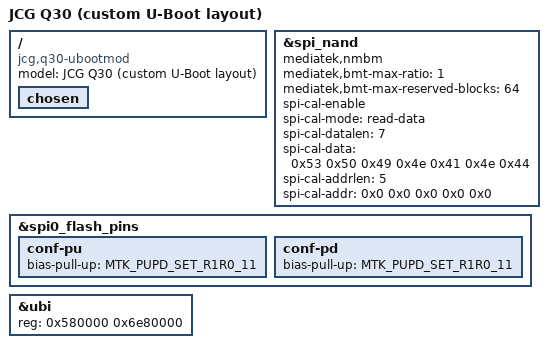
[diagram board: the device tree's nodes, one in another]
// SPDX-License-Identifier: GPL-2.0-or-later OR MIT
/*
 * JCG Q30 / Q30 PRO (custom U-Boot layout)
 *
 * Ported from the ImmortalWrt openwrt-23.05 mt7981b-jcg-q30-ubootmod.dts.
 * The vendor "unbrickable" U-Boot (kept in the "fip" partition) boots a
 * FIT image from the "kernel" UBI volume and keeps its environment in
 * the "u-boot-env" MTD partition, so this variant keeps the classic
 * kernel/rootfs/rootfs_data UBI layout instead of the single "fit"
 * volume used by the OpenWrt U-Boot layout.
 *
 * Copyright (C) 2023 Tianling Shen <cnsztl@immortalwrt.org>
 */

/dts-v1/;
#include <dt-bindings/pinctrl/mt65xx.h>

#include "mt7981b-jcg-q30-pro.dts"

/ {
	model = "JCG Q30 (custom U-Boot layout)";

	compatible = "jcg,q30-ubootmod", "mediatek,mt7981";

	/* The vendor U-Boot environment carries the bootargs
	 * (root=/dev/ubiblock0_x rootfstype=squashfs); do not force
	 * the OpenWrt U-Boot layout's "root=/dev/fit0" here.
	 */
	chosen {
		/delete-property/ bootargs-append;
		/delete-property/ rootdisk;
	};
};

&spi_nand {
	/* 6.6's MTK_BMT module (CONFIG_MTD_NAND_MTK_BMT=y in the
	 * mediatek/filogic kernel config) provides NMBM remapping;
	 * mtk_bmt_nmbm.c still parses the bmt-max-* tuning
	 * properties, kept as in the 23.05 ubootmod DTS.
	 */
	mediatek,nmbm;
	mediatek,bmt-max-ratio = <1>;
	mediatek,bmt-max-reserved-blocks = <64>;

	spi-cal-enable;
	spi-cal-mode = "read-data";
	spi-cal-datalen = <7>;
	spi-cal-data = /bits/ 8 <0x53 0x50 0x49 0x4e 0x41 0x4e 0x44>;
	spi-cal-addrlen = <5>;
	spi-cal-addr = /bits/ 32 <0x0 0x0 0x0 0x0 0x0>;
};

&spi0_flash_pins {
	conf-pu {
		/delete-property/ mediatek,pull-up-adv;
		bias-pull-up = <MTK_PUPD_SET_R1R0_11>;
	};

	conf-pd {
		/delete-property/ mediatek,pull-up-adv;
		bias-pull-up = <MTK_PUPD_SET_R1R0_11>;
	};
};

&ubi {
	/* Vendor U-Boot scans the UBI partition with the stock
	 * geometry; keep the 23.05 ubootmod size.
	 */
	reg = <0x580000 0x6e80000>;

	/delete-node/ volumes;
};
